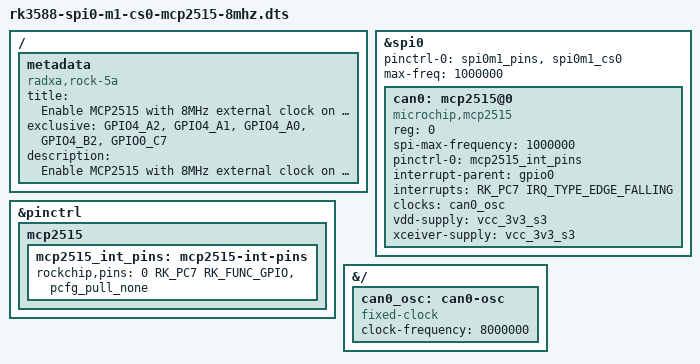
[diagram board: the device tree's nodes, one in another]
/dts-v1/;
/plugin/;

#include <dt-bindings/gpio/gpio.h>
#include <dt-bindings/pinctrl/rockchip.h>
#include <dt-bindings/interrupt-controller/irq.h>

/ {
	metadata {
		title = "Enable MCP2515 with 8MHz external clock on SPI0-M1 over CS0";
		compatible = "radxa,rock-5a", "radxa,rock-5c", "radxa,rock-5d", "radxa,cm5-io";
		exclusive = "GPIO4_A2", "GPIO4_A1", "GPIO4_A0", "GPIO4_B2", "GPIO0_C7";
		description = "Enable MCP2515 with 8MHz external clock on SPI0-M1 over CS0.
MCP2515 is a SPI CAN controller from Microchip.
On Radxa CM5 IO, the interrupt pin is pin 31.
On Radxa ROCK 5A, the interrupt pin is pin 27.
On Radxa ROCK 5C, the interrupt pin is pin 27.
On Radxa ROCK 5D, the interrupt pin is pin 27.
";
	};
};

&spi0 {
	status = "okay";
	pinctrl-names = "default";
	pinctrl-0 = <&spi0m1_pins &spi0m1_cs0>;
	#address-cells = <1>;
	#size-cells = <0>;
	max-freq = <1000000>;

	can0: mcp2515@0 {
		status = "okay";
		compatible = "microchip,mcp2515";
		reg = <0>;
		spi-max-frequency = <1000000>;

		pinctrl-names = "default";
		pinctrl-0 = <&mcp2515_int_pins>;

		interrupt-parent = <&gpio0>;
		interrupts = <RK_PC7 IRQ_TYPE_EDGE_FALLING>;

		clocks = <&can0_osc>;
		vdd-supply = <&vcc_3v3_s3>;
		xceiver-supply = <&vcc_3v3_s3>;
	};
};

&pinctrl {
	mcp2515 {
		mcp2515_int_pins: mcp2515-int-pins {
			rockchip,pins = <0 RK_PC7 RK_FUNC_GPIO &pcfg_pull_none>;
		};
	};
};

&{/} {
	can0_osc: can0-osc {
		compatible = "fixed-clock";
		#clock-cells = <0>;
		clock-frequency  = <8000000>;
	};
};
